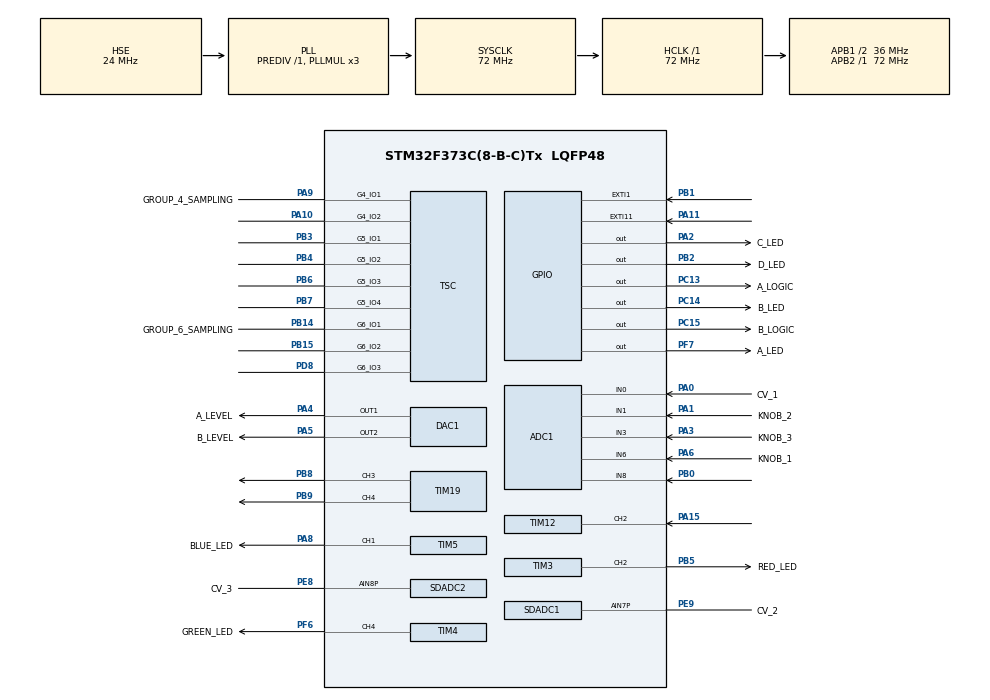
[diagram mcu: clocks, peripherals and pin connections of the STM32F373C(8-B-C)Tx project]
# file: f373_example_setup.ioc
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ADC1.Channel-0\#ChannelRegularConversion=ADC_CHANNEL_0
ADC1.Channel-1\#ChannelRegularConversion=ADC_CHANNEL_1
ADC1.Channel-2\#ChannelRegularConversion=ADC_CHANNEL_3
ADC1.Channel-3\#ChannelRegularConversion=ADC_CHANNEL_8
ADC1.ContinuousConvMode=ENABLE
ADC1.DataAlign=ADC_DATAALIGN_RIGHT
ADC1.DiscontinuousConvMode=DISABLE
ADC1.EnableAnalogWatchDog=false
ADC1.EnableRegularConversion=ENABLE
ADC1.ExternalTrigConv=ADC_SOFTWARE_START
ADC1.InjNumberOfConversion=0
ADC1.NbrOfConversion=4
ADC1.NbrOfConversionFlag=1
ADC1.Rank-0\#ChannelRegularConversion=1
ADC1.Rank-1\#ChannelRegularConversion=2
ADC1.Rank-2\#ChannelRegularConversion=3
ADC1.Rank-3\#ChannelRegularConversion=4
ADC1.SamplingTime-0\#ChannelRegularConversion=ADC_SAMPLETIME_71CYCLES_5
ADC1.SamplingTime-1\#ChannelRegularConversion=ADC_SAMPLETIME_71CYCLES_5
ADC1.SamplingTime-2\#ChannelRegularConversion=ADC_SAMPLETIME_71CYCLES_5
ADC1.SamplingTime-3\#ChannelRegularConversion=ADC_SAMPLETIME_71CYCLES_5
ADC1.ScanConvMode=ADC_SCAN_ENABLE
ADC1.master=1
DAC1.DAC_OutputBuffer=DAC_OUTPUTBUFFER_DISABLE
DAC1.DAC_OutputBuffer2=DAC_OUTPUTBUFFER_DISABLE
DAC1.DAC_Trigger=DAC_TRIGGER_T6_TRGO
DAC1.DAC_Trigger2=DAC_TRIGGER_T6_TRGO
DAC2.DAC_OutputBuffer=DAC_OUTPUTBUFFER_DISABLE
DAC2.DAC_Trigger=DAC_TRIGGER_T6_TRGO
Dma.ADC1.0.Direction=DMA_PERIPH_TO_MEMORY
Dma.ADC1.0.Instance=DMA1_Channel1
Dma.ADC1.0.MemDataAlignment=DMA_MDATAALIGN_WORD
Dma.ADC1.0.MemInc=DMA_MINC_ENABLE
Dma.ADC1.0.Mode=DMA_CIRCULAR
Dma.ADC1.0.PeriphDataAlignment=DMA_PDATAALIGN_WORD
Dma.ADC1.0.PeriphInc=DMA_PINC_DISABLE
Dma.ADC1.0.Priority=DMA_PRIORITY_LOW
Dma.DAC1_CH1.2.Direction=DMA_MEMORY_TO_PERIPH
Dma.DAC1_CH1.2.Instance=DMA1_Channel3
Dma.DAC1_CH1.2.MemDataAlignment=DMA_MDATAALIGN_WORD
Dma.DAC1_CH1.2.MemInc=DMA_MINC_ENABLE
Dma.DAC1_CH1.2.Mode=DMA_CIRCULAR
Dma.DAC1_CH1.2.PeriphDataAlignment=DMA_PDATAALIGN_WORD
Dma.DAC1_CH1.2.PeriphInc=DMA_PINC_DISABLE
Dma.DAC1_CH1.2.Priority=DMA_PRIORITY_HIGH
Dma.DAC1_CH2.3.Direction=DMA_MEMORY_TO_PERIPH
Dma.DAC1_CH2.3.Instance=DMA1_Channel4
Dma.DAC1_CH2.3.MemDataAlignment=DMA_MDATAALIGN_WORD
Dma.DAC1_CH2.3.MemInc=DMA_MINC_ENABLE
Dma.DAC1_CH2.3.Mode=DMA_CIRCULAR
Dma.DAC1_CH2.3.PeriphDataAlignment=DMA_PDATAALIGN_WORD
Dma.DAC1_CH2.3.PeriphInc=DMA_PINC_DISABLE
Dma.DAC1_CH2.3.Priority=DMA_PRIORITY_HIGH
Dma.DAC2_CH1.1.Direction=DMA_MEMORY_TO_PERIPH
Dma.DAC2_CH1.1.Instance=DMA1_Channel5
Dma.DAC2_CH1.1.MemDataAlignment=DMA_MDATAALIGN_WORD
Dma.DAC2_CH1.1.MemInc=DMA_MINC_ENABLE
Dma.DAC2_CH1.1.Mode=DMA_NORMAL
Dma.DAC2_CH1.1.PeriphDataAlignment=DMA_PDATAALIGN_WORD
Dma.DAC2_CH1.1.PeriphInc=DMA_PINC_DISABLE
Dma.DAC2_CH1.1.Priority=DMA_PRIORITY_VERY_HIGH
Dma.Request0=ADC1
Dma.Request1=DAC2_CH1
Dma.Request2=DAC1_CH1
Dma.Request3=DAC1_CH2
Dma.Request4=SDADC1
Dma.Request5=SDADC2
Dma.SDADC1.4.Direction=DMA_PERIPH_TO_MEMORY
Dma.SDADC1.4.Instance=DMA2_Channel3
Dma.SDADC1.4.MemDataAlignment=DMA_MDATAALIGN_WORD
Dma.SDADC1.4.MemInc=DMA_MINC_ENABLE
Dma.SDADC1.4.Mode=DMA_CIRCULAR
Dma.SDADC1.4.PeriphDataAlignment=DMA_PDATAALIGN_WORD
Dma.SDADC1.4.PeriphInc=DMA_PINC_DISABLE
Dma.SDADC1.4.Priority=DMA_PRIORITY_HIGH
Dma.SDADC2.5.Direction=DMA_PERIPH_TO_MEMORY
Dma.SDADC2.5.Instance=DMA2_Channel4
Dma.SDADC2.5.MemDataAlignment=DMA_MDATAALIGN_WORD
Dma.SDADC2.5.MemInc=DMA_MINC_ENABLE
Dma.SDADC2.5.Mode=DMA_CIRCULAR
Dma.SDADC2.5.PeriphDataAlignment=DMA_PDATAALIGN_WORD
Dma.SDADC2.5.PeriphInc=DMA_PINC_DISABLE
Dma.SDADC2.5.Priority=DMA_PRIORITY_HIGH
Mcu.Family=STM32F3
Mcu.Name=STM32F373C(8-B-C)Tx
Mcu.Package=LQFP48
NVIC.DMA1_Channel1_IRQn=true\:1\:0\:true\:false\:true\:false
NVIC.DMA1_Channel3_IRQn=true\:2\:0\:true\:false\:true\:false
NVIC.DMA1_Channel4_IRQn=true\:3\:0\:true\:false\:true\:false
NVIC.DMA1_Channel5_IRQn=true\:0\:0\:false\:false\:true\:false
NVIC.DMA2_Channel3_IRQn=true\:1\:0\:true\:false\:true\:false
NVIC.DMA2_Channel4_IRQn=true\:1\:0\:true\:false\:true\:false
NVIC.EXTI15_10_IRQn=true\:0\:3\:true\:false\:true\:true
NVIC.EXTI1_IRQn=true\:2\:0\:true\:false\:true\:true
NVIC.PriorityGroup=NVIC_PRIORITYGROUP_2
NVIC.TIM12_IRQn=true\:0\:0\:false\:false\:true\:true
NVIC.TIM13_IRQn=true\:3\:0\:true\:false\:true\:true
NVIC.TIM16_IRQn=true\:1\:0\:true\:false\:true\:true
NVIC.TIM17_IRQn=true\:1\:0\:true\:false\:true\:true
NVIC.TIM7_IRQn=true\:2\:0\:true\:false\:true\:true
PA0.GPIO_Label=CV_1
PA0.Mode=IN0
PA0.Signal=ADC1_IN0
PA1.GPIO_Label=KNOB_2
PA1.Mode=IN1
PA1.Signal=ADC1_IN1
PA10.Mode=G4_IO2-Channel
PA10.Signal=TSC_G4_IO2
PA11.Signal=GPXTI11
PA12.Signal=S_TIM16_CH1
PA13.Mode=Serial_Wire
PA13.Signal=SYS_JTMS-SWDIO
PA14.Mode=Serial_Wire
PA14.Signal=SYS_JTCK-SWCLK
PA15.Signal=S_TIM12_CH2
PA2.GPIO_Label=C_LED
PA2.Signal=GPIO_Output
PA3.GPIO_Label=KNOB_3
PA3.Mode=IN3
PA3.Signal=ADC1_IN3
PA4.GPIO_Label=A_LEVEL
PA4.Signal=COMP_DAC11_group
PA5.GPIO_Label=B_LEVEL
PA5.Signal=COMP_DAC12_group
PA6.GPIO_Label=KNOB_1
PA6.Signal=SharedAnalog_PA6
PA8.GPIO_Label=BLUE_LED
PA8.Signal=S_TIM5_CH1_ETR
PA9.GPIO_Label=GROUP_4_SAMPLING
PA9.Mode=G4_IO1-Sampling
PA9.Signal=TSC_G4_IO1
PB0.Mode=IN8
PB0.Signal=ADC1_IN8
PB1.GPIO_ModeDefaultEXTI=GPIO_MODE_IT_RISING_FALLING
PB1.Signal=GPXTI1
PB14.GPIO_Label=GROUP_6_SAMPLING
PB14.Mode=G6_IO1-Sampling
PB14.Signal=TSC_G6_IO1
PB15.Mode=G6_IO2-Channel
PB15.Signal=TSC_G6_IO2
PB2.GPIO_Label=D_LED
PB2.Signal=GPIO_Output
PB3.Mode=G5_IO1-Channel
PB3.Signal=TSC_G5_IO1
PB4.Mode=G5_IO2-Sampling
PB4.Signal=TSC_G5_IO2
PB5.GPIO_Label=RED_LED
PB5.Signal=S_TIM3_CH2
PB6.Mode=G5_IO3-Channel
PB6.Signal=TSC_G5_IO3
PB7.Mode=G5_IO4-Channel
PB7.Signal=TSC_G5_IO4
PB8.Signal=S_TIM19_CH3
PB9.Signal=S_TIM19_CH4
PC13.GPIO_Label=A_LOGIC
PC13.Signal=GPIO_Output
PC14-OSC32_IN.GPIO_Label=B_LED
PC14-OSC32_IN.Signal=GPIO_Output
PC15-OSC32_OUT.GPIO_Label=B_LOGIC
PC15-OSC32_OUT.Signal=GPIO_Output
PD8.Mode=G6_IO3-Channel
PD8.Signal=TSC_G6_IO3
PE8.GPIO_Label=CV_3
PE8.Mode=IN8-Single-Ended
PE8.Signal=SDADC2_AIN8P
PE9.GPIO_Label=CV_2
PE9.Mode=IN7-Single-Ended
PE9.Signal=SDADC1_AIN7P
PF0-OSC_IN.Mode=HSE-External-Oscillator
PF0-OSC_IN.Signal=RCC_OSC_IN
PF1-OSC_OUT.Mode=HSE-External-Oscillator
PF1-OSC_OUT.Signal=RCC_OSC_OUT
PF6.GPIO_Label=GREEN_LED
PF6.Signal=S_TIM4_CH4
PF7.GPIO_Label=A_LED
PF7.Signal=GPIO_Output
ProjectManager.HeapSize=0x200
ProjectManager.StackSize=0x400
ProjectManager.TargetToolchain=SW4STM32
RCC.AHBFreq_Value=72000000
RCC.APB1CLKDivider=RCC_HCLK_DIV2
RCC.APB1Freq_Value=36000000
RCC.APB1TimFreq_Value=72000000
RCC.APB2Freq_Value=72000000
RCC.APB2TimFreq_Value=72000000
RCC.CortexFreq_Value=72000000
RCC.HCLKFreq_Value=72000000
RCC.HSE_VALUE=24000000
RCC.HSI_VALUE=8000000
RCC.LSE_VALUE=32768
RCC.PLLMUL=RCC_PLL_MUL3
RCC.PLLSourceVirtual=RCC_PLLSOURCE_HSE
RCC.PRESCALERUSB=RCC_USBCLKSOURCE_PLL_DIV1_5
RCC.SDADCPresc=RCC_SDADCSYSCLK_DIV12
RCC.SYSCLKFreq_VALUE=72000000
RCC.SYSCLKSource=RCC_SYSCLKSOURCE_PLLCLK
RCC.USBFreq_Value=48000000
SDADC1.Channel-4\#ChannelRegularConversion=SDADC_CHANNEL_7
SDADC1.CommonMode0=SDADC_COMMON_MODE_VDDA_2
SDADC1.ConfIndex-4\#ChannelRegularConversion=SDADC_CONF_INDEX_0
SDADC1.ContinuousMode=SDADC_CONTINUOUS_CONV_ON
SDADC1.EnableInjectedConversion=DISABLE
SDADC1.EnableRegularconversion=ENABLE
SDADC1.FastConversionMode=SDADC_FAST_CONV_ENABLE
SDADC1.Gain0=SDADC_GAIN_1_2
SDADC1.IdleLowPowerMode=SDADC_LOWPOWER_NONE
SDADC1.InputMode0=SDADC_INPUT_MODE_SE_OFFSET
SDADC1.MultimodeType=__NULL
SDADC1.NbrOfConversionFlag=1
SDADC1.Offset0=0
SDADC1.Rank-4\#ChannelRegularConversion=1
SDADC1.SlowClockMode=SDADC_SLOW_CLOCK_DISABLE
SDADC1.Trigger=SDADC_SOFTWARE_TRIGGER
SDADC2.Channel-0\#ChannelRegularConversion=SDADC_CHANNEL_8
SDADC2.CommonMode0=SDADC_COMMON_MODE_VDDA_2
SDADC2.ConfIndex-0\#ChannelRegularConversion=SDADC_CONF_INDEX_0
SDADC2.ContinuousMode=SDADC_CONTINUOUS_CONV_ON
SDADC2.EnableInjectedConversion=DISABLE
SDADC2.EnableRegularconversion=ENABLE
SDADC2.FastConversionMode=SDADC_FAST_CONV_ENABLE
SDADC2.Gain0=SDADC_GAIN_1_2
SDADC2.IdleLowPowerMode=SDADC_LOWPOWER_NONE
SDADC2.InputMode0=SDADC_INPUT_MODE_SE_OFFSET
SDADC2.NbrOfConversionFlag=1
SDADC2.Offset0=0
SDADC2.Rank-0\#ChannelRegularConversion=1
SDADC2.ReferenceVoltage=SDADC_VREF_EXT
SDADC2.SlowClockMode=SDADC_SLOW_CLOCK_DISABLE
SDADC2.Trigger=SDADC_SOFTWARE_TRIGGER
SH.COMP_DAC11_group.0=DAC1_OUT1,DAC_OUT1
SH.COMP_DAC12_group.0=DAC1_OUT2,Enable_DAC_OUT2
SH.S_TIM12_CH2.0=TIM12_CH2,Input_Capture2_from_TI2
SH.S_TIM16_CH1.0=TIM16_CH1
SH.S_TIM19_CH3.0=TIM19_CH3,Output Compare3 CH3
SH.S_TIM19_CH4.0=TIM19_CH4,Output Compare4 CH4
SH.S_TIM3_CH2.0=TIM3_CH2,PWM Generation2 CH2
SH.S_TIM4_CH4.0=TIM4_CH4,PWM Generation4 CH4
SH.S_TIM5_CH1_ETR.0=TIM5_CH1,PWM Generation1 CH1
SH.SharedAnalog_PA6.0=ADC1_IN6,IN6
SH.SharedAnalog_PA6.1=DAC2_OUT1,DAC_OUT1
TIM12.Channel-Input_Capture2_from_TI2=TIM_CHANNEL_2
TIM12.ICPolarity_CH2=TIM_INPUTCHANNELPOLARITY_FALLING
TIM18.Period=31
TIM18.Prescaler=1
TIM18.TIM_MasterOutputTrigger=TIM_TRGO_UPDATE
TIM19.Channel-Output\ Compare3\ CH3=TIM_CHANNEL_3
TIM19.Channel-Output\ Compare4\ CH4=TIM_CHANNEL_4
TIM3.Channel-PWM\ Generation2\ CH2=TIM_CHANNEL_2
TIM3.Period=4095
TIM3.Prescaler=1
TIM3.Pulse-PWM\ Generation2\ CH2=0
TIM4.Channel-PWM\ Generation4\ CH4=TIM_CHANNEL_4
TIM4.Period=4095
TIM4.Prescaler=1-1
TIM5.Channel-PWM\ Generation1\ CH1=TIM_CHANNEL_1
TIM5.Period=4095
TIM5.Prescaler=1-1
TIM6.Period=1000
TIM6.Prescaler=1-1
TIM6.TIM_MasterOutputTrigger=TIM_TRGO_UPDATE
TOUCHSENSING.IO_3CH_LIN_H_NBR1_CH1=G5_IO4
TOUCHSENSING.IO_3CH_LIN_H_NBR1_CH2=G5_IO3
TOUCHSENSING.IO_3CH_LIN_H_NBR1_CH3=G5_IO1
TOUCHSENSING.IO_TOUCHKEY1=G4_IO2
TOUCHSENSING.IO_TOUCHKEY2=G6_IO2
TOUCHSENSING.IO_TOUCHKEY3=G6_IO3
TOUCHSENSING.IO_TOUCHKEY4=G4_IO2
TOUCHSENSING.IO_TOUCHKEY5=G6_IO3
TOUCHSENSING.IO_TOUCHKEY6=G6_IO2
TOUCHSENSING.IO_TOUCHKEY_B2=G5_IO2
TOUCHSENSING.IO_TOUCHKEY_B3=G6_IO2
TOUCHSENSING.IO_TOUCHKEY_B4=G5_IO2
TOUCHSENSING.IO_TOUCHKEY_B5=G6_IO3
TOUCHSENSING.IO_TOUCHKEY_B6=G4_IO2
TOUCHSENSING.TSLPRM_CALIB_SAMPLES=16
TOUCHSENSING.TSLPRM_DELAY_DISCHARGE_ALL=10
TOUCHSENSING.TSLPRM_SENSORS_DATAS=TSLPRM_USE_3CH_LIN_H_NBR1 3 1 1 1 TSLPRM_TOTAL_TOUCHKEYS 2 2 1 
TOUCHSENSING.TSLPRM_TICK_FREQ=125
TOUCHSENSING.TSLPRM_TKEY_CALIB_TH=250
TOUCHSENSING.TSLPRM_TKEY_DETECT_IN_TH=100
TOUCHSENSING.TSLPRM_TKEY_DETECT_OUT_TH=50
TOUCHSENSING.TSLPRM_TOTAL_TOUCHKEYS=3
TOUCHSENSING.TSLPRM_TOTAL_TOUCHKEYS_B=0
TOUCHSENSING.TSLPRM_USE_3CH_LIN_H=1
TOUCHSENSING.TSLPRM_USE_3CH_LIN_H_B_NBR=0
TOUCHSENSING.TSLPRM_USE_3CH_LIN_H_NBR=1
TOUCHSENSING.TSLPRM_USE_PROX=0
TOUCHSENSING.TSLPRM_USE_ZONE=0
TSC.CTPulseHighLength=TSC_CTPH_5CYCLES
TSC.CTPulseLowLength=TSC_CTPL_5CYCLES
TSC.PulseGeneratorPrescaler=TSC_PG_PRESC_DIV4
VP_SDADC1_CONF0.Mode=ConfigZero
VP_SDADC2_CONF0.Mode=ConfigZero
VP_TIM13_VS_ClockSourceINT.Mode=Enable_Timer
VP_TIM14_VS_ClockSourceINT.Mode=Enable_Timer
VP_TIM15_VS_ClockSourceINT.Mode=Internal
VP_TIM16_VS_ClockSourceINT.Mode=Enable_Timer
VP_TIM17_VS_ClockSourceINT.Mode=Enable_Timer
VP_TIM18_VS_ClockSourceINT.Mode=Enable_Timer
VP_TIM19_VS_ClockSourceINT.Mode=Internal
VP_TIM6_VS_ClockSourceINT.Mode=Enable_Timer
VP_TIM7_VS_ClockSourceINT.Mode=Enable_Timer
VP_TOUCHSENSING_VS_TOUCHSENSING.Mode=TouchSensing_Enabled
board=f373_example_setup

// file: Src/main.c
/**
  ******************************************************************************
  * @file           : main.c
  * @brief          : Main program body
  ******************************************************************************
  * This notice applies to any and all portions of this file
  * that are not between comment pairs USER CODE BEGIN and
  * USER CODE END. Other portions of this file, whether
  * inserted by the user or by software development tools
  * are owned by their respective copyright owners.
  *
  * Copyright (c) 2018 STMicroelectronics International N.V.
  * All rights reserved.
  *
  * Redistribution and use in source and binary forms, with or without
  * modification, are permitted, provided that the following conditions are met:
  *
  * 1. Redistribution of source code must retain the above copyright notice,
  *    this list of conditions and the following disclaimer.
  * 2. Redistributions in binary form must reproduce the above copyright notice,
  *    this list of conditions and the following disclaimer in the documentation
  *    and/or other materials provided with the distribution.
  * 3. Neither the name of STMicroelectronics nor the names of other
  *    contributors to this software may be used to endorse or promote products
  *    derived from this software without specific written permission.
  * 4. This software, including modifications and/or derivative works of this
  *    software, must execute solely and exclusively on microcontroller or
  *    microprocessor devices manufactured by or for STMicroelectronics.
  * 5. Redistribution and use of this software other than as permitted under
  *    this license is void and will automatically terminate your rights under
  *    this license.
  *
  * THIS SOFTWARE IS PROVIDED BY STMICROELECTRONICS AND CONTRIBUTORS "AS IS"
  * AND ANY EXPRESS, IMPLIED OR STATUTORY WARRANTIES, INCLUDING, BUT NOT
  * LIMITED TO, THE IMPLIED WARRANTIES OF MERCHANTABILITY, FITNESS FOR A
  * PARTICULAR PURPOSE AND NON-INFRINGEMENT OF THIRD PARTY INTELLECTUAL PROPERTY
  * RIGHTS ARE DISCLAIMED TO THE FULLEST EXTENT PERMITTED BY LAW. IN NO EVENT
  * SHALL STMICROELECTRONICS OR CONTRIBUTORS BE LIABLE FOR ANY DIRECT, INDIRECT,
  * INCIDENTAL, SPECIAL, EXEMPLARY, OR CONSEQUENTIAL DAMAGES (INCLUDING, BUT NOT
  * LIMITED TO, PROCUREMENT OF SUBSTITUTE GOODS OR SERVICES; LOSS OF USE, DATA,
  * OR PROFITS; OR BUSINESS INTERRUPTION) HOWEVER CAUSED AND ON ANY THEORY OF
  * LIABILITY, WHETHER IN CONTRACT, STRICT LIABILITY, OR TORT (INCLUDING
  * NEGLIGENCE OR OTHERWISE) ARISING IN ANY WAY OUT OF THE USE OF THIS SOFTWARE,
  * EVEN IF ADVISED OF THE POSSIBILITY OF SUCH DAMAGE.
  *
  ******************************************************************************
  */
#include "main.h"
#include "stm32f3xx_hal.h"
#include "adc.h"
#include "dac.h"
#include "dma.h"
#include "sdadc.h"
#include "tim.h"
#include "touchsensing.h"
#include "tsc.h"
#include "gpio.h"

/* USER CODE BEGIN Includes */

uint32_t tsl_status;

extern TSL_LinRotData_T * MyLinRots;

#include "simple_wavetable.h"
#include "via_rev5_hardware_io.h"

/* USER CODE END Includes */

/* USER CODE BEGIN PV */
/* Private variables ---------------------------------------------------------*/

/* USER CODE END PV */

void SystemClock_Config(void);

/* USER CODE BEGIN PFP */
/* Private function prototypes -----------------------------------------------*/

/* USER CODE END PFP */

int main(void)
{

  /* MCU Configuration----------------------------------------------------------*/

  /* Reset of all peripherals, Initializes the Flash interface and the Systick. */
  HAL_Init();

  /* Configure the system clock */
  SystemClock_Config();

  /* Initialize all configured peripherals */
  MX_GPIO_Init();
  MX_DMA_Init();
  MX_ADC1_Init();
  MX_SDADC1_Init();
  MX_SDADC2_Init();
  MX_TIM3_Init();
  MX_TIM4_Init();
  MX_TIM5_Init();
  MX_TIM13_Init();
  MX_TIM16_Init();
  MX_TIM17_Init();
  MX_TSC_Init();
  MX_TIM6_Init();
  MX_TIM7_Init();
  MX_TIM18_Init();
  MX_TOUCHSENSING_Init();
  MX_DAC1_Init();
  MX_DAC2_Init();
  MX_TIM19_Init();
  MX_TIM15_Init();
  MX_TIM14_Init();
  MX_TIM12_Init();
  /* USER CODE BEGIN 2 */

	tsl_user_Init();

	HAL_TIM_Base_Start(&htim3);
	HAL_TIM_PWM_Start(&htim3, TIM_CHANNEL_2);
	HAL_TIM_Base_Start(&htim4);
	HAL_TIM_PWM_Start(&htim4, TIM_CHANNEL_4);
	HAL_TIM_Base_Start(&htim5);
	HAL_TIM_PWM_Start(&htim5, TIM_CHANNEL_1);

  /* USER CODE END 2 */

  /* Infinite loop */
  while (1)
  {

	  tsl_status = tsl_user_Exec();

	if (tsl_status != TSL_USER_STATUS_BUSY) {
		SET_RED_LED(MyLinRots->Position << 4);
	} else {
	}

  }

}

void SystemClock_Config(void)
{

  RCC_OscInitTypeDef RCC_OscInitStruct;
  RCC_ClkInitTypeDef RCC_ClkInitStruct;
  RCC_PeriphCLKInitTypeDef PeriphClkInit;

    /**Initializes the CPU, AHB and APB busses clocks
    */
  RCC_OscInitStruct.OscillatorType = RCC_OSCILLATORTYPE_HSE;
  RCC_OscInitStruct.HSEState = RCC_HSE_ON;
  RCC_OscInitStruct.HSEPredivValue = RCC_HSE_PREDIV_DIV1;
  RCC_OscInitStruct.HSIState = RCC_HSI_ON;
  RCC_OscInitStruct.PLL.PLLState = RCC_PLL_ON;
  RCC_OscInitStruct.PLL.PLLSource = RCC_PLLSOURCE_HSE;
  RCC_OscInitStruct.PLL.PLLMUL = RCC_PLL_MUL3;
  if (HAL_RCC_OscConfig(&RCC_OscInitStruct) != HAL_OK)
  {
    _Error_Handler(__FILE__, __LINE__);
  }

    /**Initializes the CPU, AHB and APB busses clocks
    */
  RCC_ClkInitStruct.ClockType = RCC_CLOCKTYPE_HCLK|RCC_CLOCKTYPE_SYSCLK
                              |RCC_CLOCKTYPE_PCLK1|RCC_CLOCKTYPE_PCLK2;
  RCC_ClkInitStruct.SYSCLKSource = RCC_SYSCLKSOURCE_PLLCLK;
  RCC_ClkInitStruct.AHBCLKDivider = RCC_SYSCLK_DIV1;
  RCC_ClkInitStruct.APB1CLKDivider = RCC_HCLK_DIV2;
  RCC_ClkInitStruct.APB2CLKDivider = RCC_HCLK_DIV1;

  if (HAL_RCC_ClockConfig(&RCC_ClkInitStruct, FLASH_LATENCY_2) != HAL_OK)
  {
    _Error_Handler(__FILE__, __LINE__);
  }

  PeriphClkInit.PeriphClockSelection = RCC_PERIPHCLK_ADC1|RCC_PERIPHCLK_SDADC;
  PeriphClkInit.SdadcClockSelection = RCC_SDADCSYSCLK_DIV12;
  PeriphClkInit.Adc1ClockSelection = RCC_ADC1PCLK2_DIV2;

  if (HAL_RCCEx_PeriphCLKConfig(&PeriphClkInit) != HAL_OK)
  {
    _Error_Handler(__FILE__, __LINE__);
  }

  HAL_PWREx_EnableSDADC(PWR_SDADC_ANALOG1);

  HAL_PWREx_EnableSDADC(PWR_SDADC_ANALOG2);

    /**Configure the Systick interrupt time
    */
  HAL_SYSTICK_Config(HAL_RCC_GetHCLKFreq()/1000);

    /**Configure the Systick
    */
  HAL_SYSTICK_CLKSourceConfig(SYSTICK_CLKSOURCE_HCLK);

  /* SysTick_IRQn interrupt configuration */
  HAL_NVIC_SetPriority(SysTick_IRQn, 0, 0);
}

void _Error_Handler(char *file, int line)
{
  while(1)
  {
  }
}

/************************ (C) COPYRIGHT STMicroelectronics *****END OF FILE****/
